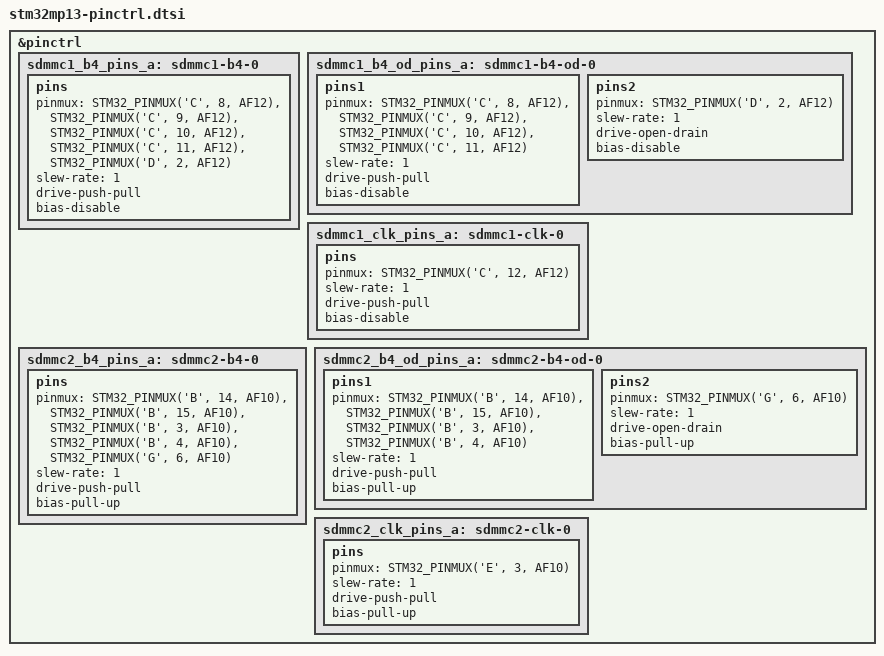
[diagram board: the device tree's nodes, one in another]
// SPDX-License-Identifier: (GPL-2.0+ OR BSD-3-Clause)
/*
 * Copyright (C) STMicroelectronics 2019 - All Rights Reserved
 * Author: Alexandre Torgue <alexandre.torgue@st.com>
 */
#include <dt-bindings/pinctrl/stm32-pinfunc.h>

&pinctrl {
	sdmmc1_b4_pins_a: sdmmc1-b4-0 {
		pins {
			pinmux = <STM32_PINMUX('C', 8, AF12)>, /* SDMMC1_D0 */
				 <STM32_PINMUX('C', 9, AF12)>, /* SDMMC1_D1 */
				 <STM32_PINMUX('C', 10, AF12)>, /* SDMMC1_D2 */
				 <STM32_PINMUX('C', 11, AF12)>, /* SDMMC1_D3 */
				 <STM32_PINMUX('D', 2, AF12)>; /* SDMMC1_CMD */
			slew-rate = <1>;
			drive-push-pull;
			bias-disable;
		};
	};

	sdmmc1_b4_od_pins_a: sdmmc1-b4-od-0 {
		pins1 {
			pinmux = <STM32_PINMUX('C', 8, AF12)>, /* SDMMC1_D0 */
				 <STM32_PINMUX('C', 9, AF12)>, /* SDMMC1_D1 */
				 <STM32_PINMUX('C', 10, AF12)>, /* SDMMC1_D2 */
				 <STM32_PINMUX('C', 11, AF12)>; /* SDMMC1_D3 */
			slew-rate = <1>;
			drive-push-pull;
			bias-disable;
		};
		pins2 {
			pinmux = <STM32_PINMUX('D', 2, AF12)>; /* SDMMC1_CMD */
			slew-rate = <1>;
			drive-open-drain;
			bias-disable;
		};
	};

	sdmmc1_clk_pins_a: sdmmc1-clk-0 {
		pins {
			pinmux = <STM32_PINMUX('C', 12, AF12)>; /* SDMMC1_CK */
			slew-rate = <1>;
			drive-push-pull;
			bias-disable;
		};
	};

	sdmmc2_b4_pins_a: sdmmc2-b4-0 {
		pins {
			pinmux = <STM32_PINMUX('B', 14, AF10)>, /* SDMMC2_D0 */
				 <STM32_PINMUX('B', 15, AF10)>, /* SDMMC2_D1 */
				 <STM32_PINMUX('B', 3, AF10)>, /* SDMMC2_D2 */
				 <STM32_PINMUX('B', 4, AF10)>, /* SDMMC2_D3 */
				 <STM32_PINMUX('G', 6, AF10)>; /* SDMMC2_CMD */
			slew-rate = <1>;
			drive-push-pull;
			bias-pull-up;
		};
	};

	sdmmc2_b4_od_pins_a: sdmmc2-b4-od-0 {
		pins1 {
			pinmux = <STM32_PINMUX('B', 14, AF10)>, /* SDMMC2_D0 */
				 <STM32_PINMUX('B', 15, AF10)>, /* SDMMC2_D1 */
				 <STM32_PINMUX('B', 3, AF10)>, /* SDMMC2_D2 */
				 <STM32_PINMUX('B', 4, AF10)>; /* SDMMC2_D3 */
			slew-rate = <1>;
			drive-push-pull;
			bias-pull-up;
		};
		pins2 {
			pinmux = <STM32_PINMUX('G', 6, AF10)>; /* SDMMC2_CMD */
			slew-rate = <1>;
			drive-open-drain;
			bias-pull-up;
		};
	};

	sdmmc2_clk_pins_a: sdmmc2-clk-0 {
		pins {
			pinmux = <STM32_PINMUX('E', 3, AF10)>; /* SDMMC2_CK */
			slew-rate = <1>;
			drive-push-pull;
			bias-pull-up;
		};
	};
};
